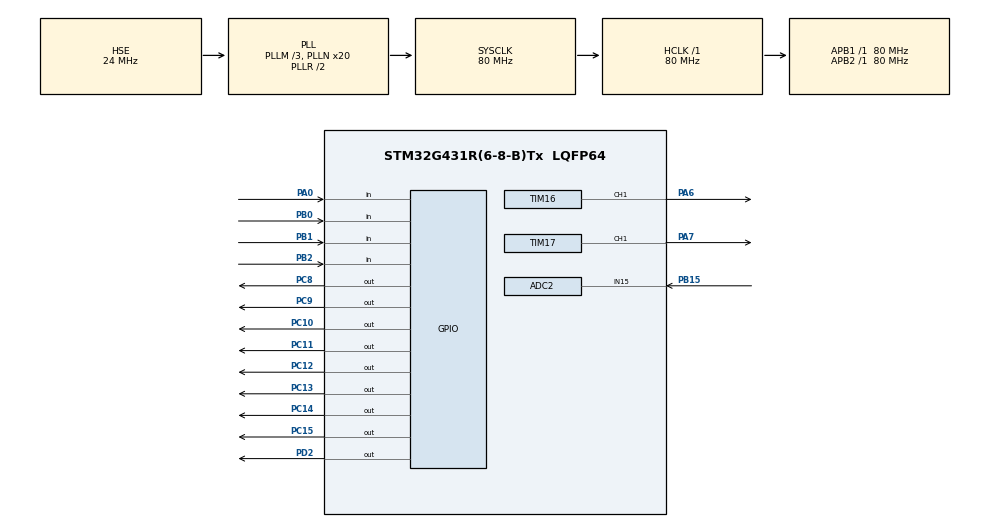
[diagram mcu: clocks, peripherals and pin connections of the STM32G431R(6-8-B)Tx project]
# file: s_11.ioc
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ADC2.Channel-0\#ChannelRegularConversion=ADC_CHANNEL_15
ADC2.ContinuousConvMode=ENABLE
ADC2.DMAContinuousRequests=ENABLE
ADC2.NbrOfConversionFlag=1
ADC2.OffsetNumber-0\#ChannelRegularConversion=ADC_OFFSET_NONE
ADC2.Rank-0\#ChannelRegularConversion=1
ADC2.SamplingTime-0\#ChannelRegularConversion=ADC_SAMPLETIME_92CYCLES_5
Dma.ADC2.0.Direction=DMA_PERIPH_TO_MEMORY
Dma.ADC2.0.EventEnable=DISABLE
Dma.ADC2.0.Instance=DMA1_Channel1
Dma.ADC2.0.MemDataAlignment=DMA_MDATAALIGN_WORD
Dma.ADC2.0.MemInc=DMA_MINC_ENABLE
Dma.ADC2.0.Mode=DMA_CIRCULAR
Dma.ADC2.0.PeriphDataAlignment=DMA_PDATAALIGN_WORD
Dma.ADC2.0.PeriphInc=DMA_PINC_DISABLE
Dma.ADC2.0.Polarity=HAL_DMAMUX_REQ_GEN_RISING
Dma.ADC2.0.Priority=DMA_PRIORITY_HIGH
Dma.ADC2.0.RequestNumber=1
Dma.ADC2.0.SignalID=NONE
Dma.ADC2.0.SyncEnable=DISABLE
Dma.ADC2.0.SyncPolarity=HAL_DMAMUX_SYNC_NO_EVENT
Dma.ADC2.0.SyncRequestNumber=1
Dma.ADC2.0.SyncSignalID=NONE
Dma.Request0=ADC2
Mcu.Family=STM32G4
Mcu.Name=STM32G431R(6-8-B)Tx
Mcu.Package=LQFP64
NVIC.DMA1_Channel1_IRQn=true\:0\:0\:false\:false\:true\:false\:true
NVIC.PriorityGroup=NVIC_PRIORITYGROUP_4
NVIC.TIM6_DAC_IRQn=true\:1\:0\:true\:false\:true\:true\:true
PA0.GPIO_Mode=GPIO_MODE_INPUT
PA0.GPIO_PuPd=GPIO_PULLUP
PA0.Signal=GPIO_Input
PA13.Mode=Serial_Wire
PA13.Signal=SYS_JTMS-SWDIO
PA14.Mode=Serial_Wire
PA14.Signal=SYS_JTCK-SWCLK
PA6.Signal=S_TIM16_CH1
PA7.Signal=S_TIM17_CH1
PB0.GPIO_Mode=GPIO_MODE_INPUT
PB0.GPIO_PuPd=GPIO_PULLUP
PB0.Signal=GPIO_Input
PB1.GPIO_Mode=GPIO_MODE_INPUT
PB1.GPIO_PuPd=GPIO_PULLUP
PB1.Signal=GPIO_Input
PB15.Mode=IN15-Single-Ended
PB15.Signal=ADC2_IN15
PB2.GPIO_Mode=GPIO_MODE_INPUT
PB2.GPIO_PuPd=GPIO_PULLUP
PB2.Signal=GPIO_Input
PC10.GPIO_ModeDefaultOutputPP=GPIO_MODE_OUTPUT_PP
PC10.GPIO_PuPd=GPIO_NOPULL
PC10.GPIO_Speed=GPIO_SPEED_FREQ_LOW
PC10.PinState=GPIO_PIN_SET
PC10.Signal=GPIO_Output
PC11.GPIO_ModeDefaultOutputPP=GPIO_MODE_OUTPUT_PP
PC11.GPIO_PuPd=GPIO_NOPULL
PC11.GPIO_Speed=GPIO_SPEED_FREQ_LOW
PC11.PinState=GPIO_PIN_SET
PC11.Signal=GPIO_Output
PC12.GPIO_ModeDefaultOutputPP=GPIO_MODE_OUTPUT_PP
PC12.GPIO_PuPd=GPIO_NOPULL
PC12.GPIO_Speed=GPIO_SPEED_FREQ_LOW
PC12.PinState=GPIO_PIN_SET
PC12.Signal=GPIO_Output
PC13.GPIO_ModeDefaultOutputPP=GPIO_MODE_OUTPUT_PP
PC13.GPIO_PuPd=GPIO_NOPULL
PC13.GPIO_Speed=GPIO_SPEED_FREQ_LOW
PC13.PinState=GPIO_PIN_SET
PC13.Signal=GPIO_Output
PC14-OSC32_IN.GPIO_ModeDefaultOutputPP=GPIO_MODE_OUTPUT_PP
PC14-OSC32_IN.GPIO_PuPd=GPIO_NOPULL
PC14-OSC32_IN.GPIO_Speed=GPIO_SPEED_FREQ_LOW
PC14-OSC32_IN.PinState=GPIO_PIN_SET
PC14-OSC32_IN.Signal=GPIO_Output
PC15-OSC32_OUT.GPIO_ModeDefaultOutputPP=GPIO_MODE_OUTPUT_PP
PC15-OSC32_OUT.GPIO_PuPd=GPIO_NOPULL
PC15-OSC32_OUT.GPIO_Speed=GPIO_SPEED_FREQ_LOW
PC15-OSC32_OUT.PinState=GPIO_PIN_SET
PC15-OSC32_OUT.Signal=GPIO_Output
PC8.GPIO_ModeDefaultOutputPP=GPIO_MODE_OUTPUT_PP
PC8.GPIO_PuPd=GPIO_NOPULL
PC8.GPIO_Speed=GPIO_SPEED_FREQ_LOW
PC8.PinState=GPIO_PIN_SET
PC8.Signal=GPIO_Output
PC9.GPIO_ModeDefaultOutputPP=GPIO_MODE_OUTPUT_PP
PC9.GPIO_PuPd=GPIO_NOPULL
PC9.GPIO_Speed=GPIO_SPEED_FREQ_LOW
PC9.PinState=GPIO_PIN_SET
PC9.Signal=GPIO_Output
PD2.GPIO_Speed=GPIO_SPEED_FREQ_MEDIUM
PD2.Signal=GPIO_Output
PF0-OSC_IN.Mode=HSE-External-Oscillator
PF0-OSC_IN.Signal=RCC_OSC_IN
PF1-OSC_OUT.Mode=HSE-External-Oscillator
PF1-OSC_OUT.Signal=RCC_OSC_OUT
ProjectManager.HeapSize=0x200
ProjectManager.StackSize=0x400
ProjectManager.TargetToolchain=MDK-ARM V5.32
RCC.ADC12Freq_Value=80000000
RCC.AHBFreq_Value=80000000
RCC.APB1Freq_Value=80000000
RCC.APB1TimFreq_Value=80000000
RCC.APB2Freq_Value=80000000
RCC.APB2TimFreq_Value=80000000
RCC.CortexFreq_Value=80000000
RCC.EXTERNAL_CLOCK_VALUE=12288000
RCC.HCLKFreq_Value=80000000
RCC.HSE_VALUE=24000000
RCC.HSI48_VALUE=48000000
RCC.HSI_VALUE=16000000
RCC.LSE_VALUE=32768
RCC.PLLM=RCC_PLLM_DIV3
RCC.PLLN=20
RCC.PLLSourceVirtual=RCC_PLLSOURCE_HSE
RCC.SYSCLKFreq_VALUE=80000000
RCC.SYSCLKSource=RCC_SYSCLKSOURCE_PLLCLK
RCC.USBFreq_Value=80000000
RCC.VCOOutputFreq_Value=160000000
SH.S_TIM16_CH1.0=TIM16_CH1,PWM Generation1 CH1
SH.S_TIM17_CH1.0=TIM17_CH1,PWM Generation1 CH1
TIM16.Channel=TIM_CHANNEL_1
TIM16.PeriodNoDither=10000-1
TIM16.Prescaler=80-1
TIM16.PulseNoDither_1=1000
TIM17.Channel=TIM_CHANNEL_1
TIM17.PeriodNoDither=5000-1
TIM17.Prescaler=80-1
TIM17.PulseNoDither_1=500
TIM6.PeriodNoDither=1000-1
TIM6.Prescaler=80-1
VP_SYS_VS_DBSignals.Mode=DisableDeadBatterySignals
VP_TIM16_VS_ClockSourceINT.Mode=Enable_Timer
VP_TIM17_VS_ClockSourceINT.Mode=Enable_Timer
VP_TIM6_VS_ClockSourceINT.Mode=Enable_Timer
board=custom

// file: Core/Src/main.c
/* USER CODE BEGIN Header */
/**
  ******************************************************************************
  * @file           : main.c
  * @brief          : Main program body
  ******************************************************************************
  * @attention
  *
  * Copyright (c) 2023 STMicroelectronics.
  * All rights reserved.
  *
  * This software is licensed under terms that can be found in the LICENSE file
  * in the root directory of this software component.
  * If no LICENSE file comes with this software, it is provided AS-IS.
  *
  ******************************************************************************
  */
/* USER CODE END Header */
#include "main.h"
#include "adc.h"
#include "dma.h"
#include "tim.h"
#include "gpio.h"

/* USER CODE BEGIN Includes */
#include "my.h"
/* USER CODE END Includes */

void SystemClock_Config(void);

int main(void)
{

  /* MCU Configuration--------------------------------------------------------*/

  /* Reset of all peripherals, Initializes the Flash interface and the Systick. */
  HAL_Init();

  /* Configure the system clock */
  SystemClock_Config();

  /* Initialize all configured peripherals */
  MX_GPIO_Init();
  MX_DMA_Init();
  MX_ADC2_Init();
  MX_TIM16_Init();
  MX_TIM17_Init();
  MX_TIM6_Init();
  /* USER CODE BEGIN 2 */
  TASK_Init();
  /* USER CODE END 2 */

  /* Infinite loop */
  /* USER CODE BEGIN WHILE */
  while (1)
  {

	 LCD_function();
	 Get_ADC();
	 KEY_function();
	 Flag_Run_fuction();

    /* USER CODE END WHILE */

  }
}

void SystemClock_Config(void)
{
  RCC_OscInitTypeDef RCC_OscInitStruct = {0};
  RCC_ClkInitTypeDef RCC_ClkInitStruct = {0};

  /** Configure the main internal regulator output voltage
  */
  HAL_PWREx_ControlVoltageScaling(PWR_REGULATOR_VOLTAGE_SCALE1);
  /** Initializes the RCC Oscillators according to the specified parameters
  * in the RCC_OscInitTypeDef structure.
  */
  RCC_OscInitStruct.OscillatorType = RCC_OSCILLATORTYPE_HSE;
  RCC_OscInitStruct.HSEState = RCC_HSE_ON;
  RCC_OscInitStruct.PLL.PLLState = RCC_PLL_ON;
  RCC_OscInitStruct.PLL.PLLSource = RCC_PLLSOURCE_HSE;
  RCC_OscInitStruct.PLL.PLLM = RCC_PLLM_DIV3;
  RCC_OscInitStruct.PLL.PLLN = 20;
  RCC_OscInitStruct.PLL.PLLP = RCC_PLLP_DIV2;
  RCC_OscInitStruct.PLL.PLLQ = RCC_PLLQ_DIV2;
  RCC_OscInitStruct.PLL.PLLR = RCC_PLLR_DIV2;
  if (HAL_RCC_OscConfig(&RCC_OscInitStruct) != HAL_OK)
  {
    Error_Handler();
  }
  /** Initializes the CPU, AHB and APB buses clocks
  */
  RCC_ClkInitStruct.ClockType = RCC_CLOCKTYPE_HCLK|RCC_CLOCKTYPE_SYSCLK
                              |RCC_CLOCKTYPE_PCLK1|RCC_CLOCKTYPE_PCLK2;
  RCC_ClkInitStruct.SYSCLKSource = RCC_SYSCLKSOURCE_PLLCLK;
  RCC_ClkInitStruct.AHBCLKDivider = RCC_SYSCLK_DIV1;
  RCC_ClkInitStruct.APB1CLKDivider = RCC_HCLK_DIV1;
  RCC_ClkInitStruct.APB2CLKDivider = RCC_HCLK_DIV1;

  if (HAL_RCC_ClockConfig(&RCC_ClkInitStruct, FLASH_LATENCY_2) != HAL_OK)
  {
    Error_Handler();
  }
}

void Error_Handler(void)
{
  __disable_irq();
  while (1)
  {
  }
}
